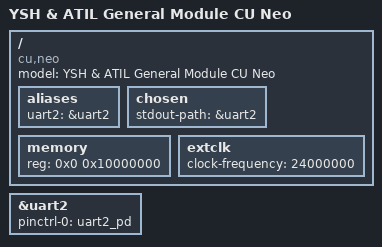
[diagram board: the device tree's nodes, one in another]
// SPDX-License-Identifier: GPL-2.0
/dts-v1/;

#include "x1000.dtsi"

/ {
	model = "YSH & ATIL General Module CU Neo";
	compatible = "cu,neo", "ingenic,x1000";

	aliases: aliases {
		uart2 = &uart2;
	};

	chosen {
		stdout-path = &uart2;
	};

	memory {
		device_type = "memory";
		reg = <0x0 0x10000000>;
	};

	extclk: extclk {
		clock-frequency = <24000000>;
	};
};

&uart2 {
	pinctrl-names = "default";
	status = "okay";
	pinctrl-0 = <&uart2_pd>;
};
